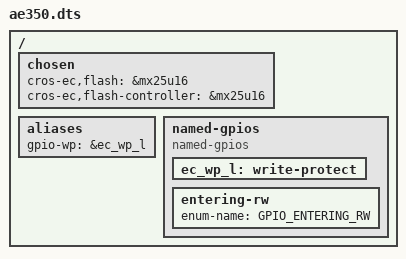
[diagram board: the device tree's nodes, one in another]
/* Copyright 2025 The ChromiumOS Authors
 * Use of this source code is governed by a BSD-style license that can be
 * found in the LICENSE file.
 */

/ {
	chosen {
		// cros-ec,bbram = &bbram;
		cros-ec,flash = &mx25u16;
		cros-ec,flash-controller = &mx25u16;
		// cros-ec,watchdog = &iwdg;
		// cros-ec,watchdog-helper = &wdg_helper;
	};

	aliases {
		gpio-wp = &ec_wp_l;
	};

	named-gpios {
		compatible = "named-gpios";

		ec_wp_l: write-protect {
			// gpios = <&gpioa 0 GPIO_INPUT>;
		};

		/* unimplemented GPIOs */
		entering-rw {
			enum-name = "GPIO_ENTERING_RW";
		};
	};
};
